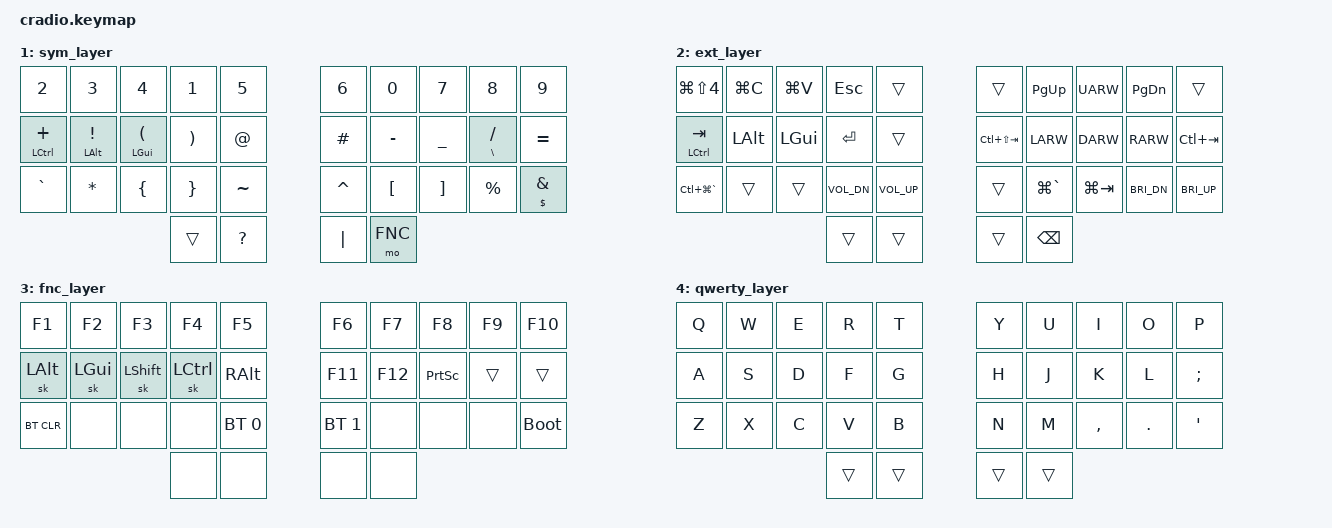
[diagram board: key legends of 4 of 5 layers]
/*
 * Copyright (c) 2020 The ZMK Contributors
 *
 * SPDX-License-Identifier: MIT
 */

#include <behaviors.dtsi>
#include <dt-bindings/zmk/keys.h>
#include <dt-bindings/zmk/bt.h>

// Layer definitions
    #define BASE 0
    #define SYM 1
    #define EXT 2
    #define FNC 3
    #define QWERTY 4
// -----------------

&mt {
   //  flavor = "tap-preferred";
   // tapping_term_ms = <200>;
};

&sk {
    ignore-modifiers;
};
	
&caps_word {
    continue-list = <UNDERSCORE MINUS>;
};

/ {

    macros {
        cmd_qwerty: cmd_qwerty {
            label = "cmd_qwerty";
            compatible = "zmk,behavior-macro";
            #binding-cells = <0>;
	    wait-ms = <0>;
	    bindings
		    = <&macro_press &mo QWERTY &kp LGUI>
		    , <&macro_pause_for_release>
		    , <&macro_release &mo QWERTY &kp LGUI>;
	};
    };

    behaviors {
        hm: homerow_mods {
            compatible = "zmk,behavior-hold-tap";
            label = "homerow mods";
            #binding-cells = <2>;
            tapping_term_ms = <200>;
            flavor = "tap-preferred";
            bindings = <&kp>, <&kp>;
        };
	
	qwert: qwert {
            compatible = "zmk,behavior-hold-tap";
            label = "qwert";
            #binding-cells = <2>;
            tapping_term_ms = <200>;
            flavor = "tap-preferred";
            bindings = <&cmd_qwerty>, <&kp>;
        };

	td0: tap_dance_0 {
            compatible = "zmk,behavior-tap-dance";
            label = "TAP_DANCE_0";
            #binding-cells = <0>;
            tapping-term-ms = <200>;
            bindings = <&sk LSHIFT>, <&caps_word>, <&kp CAPS>;
        };
    };

    keymap {
        compatible = "zmk,keymap";

        // Base alpha layer
       	default_layer {
            bindings = <
                &kp Q      &kp C      &kp L       &kp M          &kp K         &kp Z            &kp F          &kp U       &kp SQT      &kp SEMI
                &hm LCTRL I &hm LALT S &qwert &kp R &kp T &kp G     &kp P       &kp N    &hm LGUI E &hm LALT A &hm LCTRL O
		&kp Y      &kp V     &kp W       &kp D    &kp J         &kp B       &kp H          &kp COMMA   &kp DOT   &kp X
                                                  &mo EXT  &kp SPACE     &td0	     &sl SYM
            >;
        };

        // Numbers and high frequency symbols
       	sym_layer {
            bindings = <
                &kp N2   &kp N3     &kp N4      &kp N1          &kp N5      &kp N6          &kp N0         &kp N7      &kp N8     &kp N9
                &hm LCTRL PLUS   &hm LALT EXCL  &hm LGUI LPAR   &kp RPAR    &kp AT     &kp POUND          &kp MINUS         &kp UNDER      &hm BSLH FSLH     &kp EQUAL
                &kp GRAVE  &kp ASTRK     &kp LBRC      &kp RBRC          &kp TILDE      &kp CARET          &kp LBKT         &kp RBKT      &kp PRCNT     &hm DOLLAR AMPS
                                                  &trans    &kp QMARK     &kp PIPE          &mo FNC
            >;
	};

        // Main modifiers and arrow keys
	ext_layer {
	    bindings = <
                &kp LG(LS(N4)) &kp LG(C)     &kp LG(V)     &kp ESC          &trans       &trans           &kp PG_UP         &kp UARW      &kp PG_DN     &trans
                &hm LCTRL TAB     &kp LALT     &kp LGUI      &kp ENTER          &trans       &kp LC(LS(TAB))      &kp LARW       &kp DARW    &kp RARW   &kp LC(TAB)
                &kp LC(LG(GRAVE))  &trans     &trans      &kp C_VOL_DN   &kp C_VOL_UP       &trans           &kp LG(GRAVE)  &kp LG(TAB)  &kp C_BRI_DN  &kp C_BRI_UP
                                                  &trans          &trans       &trans          &kp BSPC
	    >;
	};

        // Function keys with modifiers
       	fnc_layer {
		bindings = <
		&kp F1 &kp F2 &kp F3 &kp F4 &kp F5                  &kp F6 &kp F7 &kp F8 &kp F9 &kp F10 
		&sk LALT &sk LGUI &sk LSHIFT &sk LCTRL &kp RALT     &kp F11 &kp F12  &kp PRINTSCREEN &trans &trans
		&bt BT_CLR &none &none &none &bt BT_SEL 0				    &bt BT_SEL 1 &none &none &none &bootloader 
          				           &none &none         &none &none  
		>;
	};
	
	// Qwerty layer
	    qwerty_layer {
            bindings = <
                &kp Q      &kp W      &kp E       &kp R          &kp T         &kp Y            &kp U          &kp I       &kp O      &kp P
                &kp A      &kp S      &kp D       &kp F    &kp G         &kp H       &kp J      &kp K	       &kp L       &kp SEMI
		&kp Z      &kp X      &kp C       &kp V    &kp B         &kp N       &kp M          &kp COMMA   &kp DOT    &kp SQT
                                                  &trans  &trans         &trans  &trans
            >;
	};
     };
};
